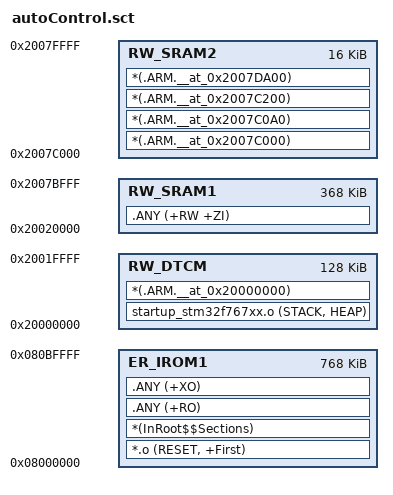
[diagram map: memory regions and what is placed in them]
; *************************************************************
; *** autoControl Flash/RAM Layout
; *** Firmware IROM : 0x08000000-0x080BFFFF (768KB)
; *** Persist Flash : 0x080C0000+ reserved for scheduler/config
; *** DTCM          : FreeRTOS heap only (CPU-only, no DMA)
; *** SRAM1         : normal RW/ZI, task stacks, lwIP heap
; *** SRAM2         : ETH DMA descriptors/buffers/RX pool only
; *************************************************************

LR_IROM1 0x08000000 0x000C0000  {
  ER_IROM1 0x08000000 0x000C0000  {
   *.o (RESET, +First)
   *(InRoot$$Sections)
   .ANY (+RO)
   .ANY (+XO)
  }

  RW_DTCM 0x20000000 0x00020000  {
   startup_stm32f767xx.o (STACK, HEAP)
   *(.ARM.__at_0x20000000)
  }

  RW_SRAM1 0x20020000 0x0005C000  {
   .ANY (+RW +ZI)
  }

  RW_SRAM2 0x2007C000 0x00004000  {
   *(.ARM.__at_0x2007C000)
   *(.ARM.__at_0x2007C0A0)
   *(.ARM.__at_0x2007C200)
   *(.ARM.__at_0x2007DA00)
  }
}
